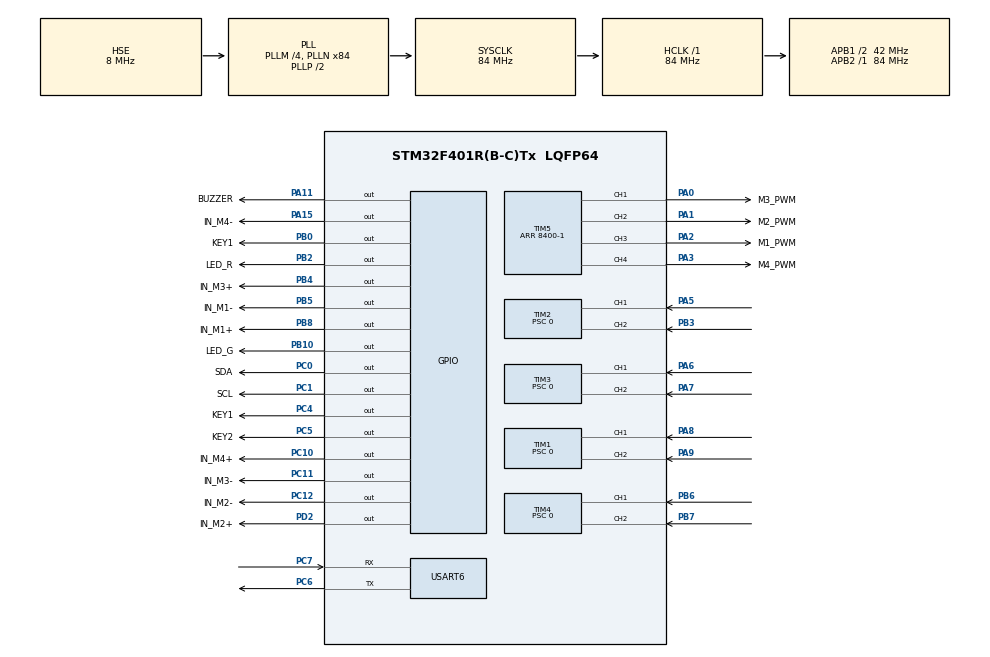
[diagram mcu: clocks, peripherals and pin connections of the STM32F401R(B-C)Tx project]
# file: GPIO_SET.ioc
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Mcu.Family=STM32F4
Mcu.Name=STM32F401R(B-C)Tx
Mcu.Package=LQFP64
NVIC.PriorityGroup=NVIC_PRIORITYGROUP_4
NVIC.TIM5_IRQn=true\:0\:0\:false\:false\:true\:true\:true\:true
NVIC.USART6_IRQn=true\:0\:0\:false\:false\:true\:true\:true\:true
PA0-WKUP.GPIO_Label=M3_PWM
PA0-WKUP.Signal=S_TIM5_CH1
PA1.GPIO_Label=M2_PWM
PA1.Signal=S_TIM5_CH2
PA11.GPIO_Label=BUZZER
PA11.Signal=GPIO_Output
PA13.Mode=Serial_Wire
PA13.Signal=SYS_JTMS-SWDIO
PA14.Mode=Serial_Wire
PA14.Signal=SYS_JTCK-SWCLK
PA15.GPIO_Label=IN_M4-
PA15.Signal=GPIO_Output
PA2.GPIO_Label=M1_PWM
PA2.Signal=S_TIM5_CH3
PA3.GPIO_Label=M4_PWM
PA3.Signal=S_TIM5_CH4
PA5.Signal=S_TIM2_CH1_ETR
PA6.Signal=S_TIM3_CH1
PA7.Signal=S_TIM3_CH2
PA8.Signal=S_TIM1_CH1
PA9.Signal=S_TIM1_CH2
PB0.GPIO_Label=KEY1
PB0.Signal=GPIO_Output
PB10.GPIO_Label=LED_G
PB10.GPIO_Speed=GPIO_SPEED_FREQ_VERY_HIGH
PB10.Signal=GPIO_Output
PB2.GPIO_Label=LED_R
PB2.Signal=GPIO_Output
PB3.Signal=S_TIM2_CH2
PB4.GPIO_Label=IN_M3+
PB4.Signal=GPIO_Output
PB5.GPIO_Label=IN_M1-
PB5.Signal=GPIO_Output
PB6.Signal=S_TIM4_CH1
PB7.Signal=S_TIM4_CH2
PB8.GPIO_Label=IN_M1+
PB8.Signal=GPIO_Output
PC0.GPIO_Label=SDA
PC0.Signal=GPIO_Output
PC1.GPIO_Label=SCL
PC1.Signal=GPIO_Output
PC10.GPIO_Label=IN_M4+
PC10.Signal=GPIO_Output
PC11.GPIO_Label=IN_M3-
PC11.Signal=GPIO_Output
PC12.GPIO_Label=IN_M2-
PC12.Signal=GPIO_Output
PC4.GPIO_Label=KEY1
PC4.Signal=GPIO_Output
PC5.GPIO_Label=KEY2
PC5.Signal=GPIO_Output
PC6.Mode=Asynchronous
PC6.Signal=USART6_TX
PC7.Mode=Asynchronous
PC7.Signal=USART6_RX
PD2.GPIO_Label=IN_M2+
PD2.Signal=GPIO_Output
PH0\ -\ OSC_IN.Mode=HSE-External-Oscillator
PH0\ -\ OSC_IN.Signal=RCC_OSC_IN
PH1\ -\ OSC_OUT.Mode=HSE-External-Oscillator
PH1\ -\ OSC_OUT.Signal=RCC_OSC_OUT
ProjectManager.HeapSize=0x200
ProjectManager.StackSize=0x400
ProjectManager.TargetToolchain=Makefile
RCC.48MHZClocksFreq_Value=42000000
RCC.AHBFreq_Value=84000000
RCC.APB1CLKDivider=RCC_HCLK_DIV2
RCC.APB1Freq_Value=42000000
RCC.APB1TimFreq_Value=84000000
RCC.APB2Freq_Value=84000000
RCC.APB2TimFreq_Value=84000000
RCC.CortexFreq_Value=84000000
RCC.HCLKFreq_Value=84000000
RCC.HSE_VALUE=8000000
RCC.HSI_VALUE=16000000
RCC.LSE_VALUE=32768
RCC.PLLM=4
RCC.PLLN=84
RCC.PLLSourceVirtual=RCC_PLLSOURCE_HSE
RCC.SYSCLKFreq_VALUE=84000000
RCC.SYSCLKSource=RCC_SYSCLKSOURCE_PLLCLK
RCC.VCOOutputFreq_Value=168000000
SH.S_TIM1_CH1.0=TIM1_CH1,Encoder_Interface
SH.S_TIM1_CH2.0=TIM1_CH2,Encoder_Interface
SH.S_TIM2_CH1_ETR.0=TIM2_CH1,Encoder_Interface
SH.S_TIM2_CH2.0=TIM2_CH2,Encoder_Interface
SH.S_TIM3_CH1.0=TIM3_CH1,Encoder_Interface
SH.S_TIM3_CH2.0=TIM3_CH2,Encoder_Interface
SH.S_TIM4_CH1.0=TIM4_CH1,Encoder_Interface
SH.S_TIM4_CH2.0=TIM4_CH2,Encoder_Interface
SH.S_TIM5_CH1.0=TIM5_CH1,PWM Generation1 CH1
SH.S_TIM5_CH2.0=TIM5_CH2,PWM Generation2 CH2
SH.S_TIM5_CH3.0=TIM5_CH3,PWM Generation3 CH3
SH.S_TIM5_CH4.0=TIM5_CH4,PWM Generation4 CH4
TIM1.EncoderMode=TIM_ENCODERMODE_TI12
TIM1.Prescaler=0
TIM2.EncoderMode=TIM_ENCODERMODE_TI12
TIM2.Prescaler=0
TIM3.EncoderMode=TIM_ENCODERMODE_TI12
TIM3.Prescaler=0
TIM4.EncoderMode=TIM_ENCODERMODE_TI12
TIM4.Prescaler=0
TIM5.AutoReloadPreload=TIM_AUTORELOAD_PRELOAD_ENABLE
TIM5.Channel-PWM\ Generation1\ CH1=TIM_CHANNEL_1
TIM5.Channel-PWM\ Generation2\ CH2=TIM_CHANNEL_2
TIM5.Channel-PWM\ Generation3\ CH3=TIM_CHANNEL_3
TIM5.Channel-PWM\ Generation4\ CH4=TIM_CHANNEL_4
TIM5.Period=8400-1
TIM5.Pulse-PWM\ Generation1\ CH1=8000
TIM5.Pulse-PWM\ Generation2\ CH2=8000
TIM5.Pulse-PWM\ Generation3\ CH3=8000
TIM5.Pulse-PWM\ Generation4\ CH4=8000
USART6.VirtualMode=VM_ASYNC
VP_TIM5_VS_ClockSourceINT.Mode=Internal
board=custom

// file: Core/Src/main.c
/* USER CODE BEGIN Header */
/**
  ******************************************************************************
  * @file           : main.c
  * @brief          : Main program body
  ******************************************************************************
  * @attention
  *
  * Copyright (c) 2024 STMicroelectronics.
  * All rights reserved.
  *
  * This software is licensed under terms that can be found in the LICENSE file
  * in the root directory of this software component.
  * If no LICENSE file comes with this software, it is provided AS-IS.
  *
  ******************************************************************************
  */
/* USER CODE END Header */
#include "main.h"
#include "tim.h"
#include "usart.h"
#include "gpio.h"

/* USER CODE BEGIN Includes */
#include "headfile.h"
/* USER CODE END Includes */

void SystemClock_Config(void);

int main(void)
{

  /* MCU Configuration--------------------------------------------------------*/

  /* Reset of all peripherals, Initializes the Flash interface and the Systick. */
  HAL_Init();

  /* Configure the system clock */
  SystemClock_Config();

  /* Initialize all configured peripherals */
  MX_GPIO_Init();
  MX_TIM1_Init();
  MX_TIM2_Init();
  MX_TIM3_Init();
  MX_TIM4_Init();
  MX_TIM5_Init();
  MX_USART6_UART_Init();
  /* USER CODE BEGIN 2 */
  task_init();
  /* USER CODE END 2 */

  /* Infinite loop */
  while (1)
  {

    /* USER CODE BEGIN 3 */
    task_do();
  }
  /* USER CODE END 3 */
}

void SystemClock_Config(void)
{
  RCC_OscInitTypeDef RCC_OscInitStruct = {0};
  RCC_ClkInitTypeDef RCC_ClkInitStruct = {0};

  /** Configure the main internal regulator output voltage
  */
  __HAL_RCC_PWR_CLK_ENABLE();
  __HAL_PWR_VOLTAGESCALING_CONFIG(PWR_REGULATOR_VOLTAGE_SCALE2);

  /** Initializes the RCC Oscillators according to the specified parameters
  * in the RCC_OscInitTypeDef structure.
  */
  RCC_OscInitStruct.OscillatorType = RCC_OSCILLATORTYPE_HSE;
  RCC_OscInitStruct.HSEState = RCC_HSE_ON;
  RCC_OscInitStruct.PLL.PLLState = RCC_PLL_ON;
  RCC_OscInitStruct.PLL.PLLSource = RCC_PLLSOURCE_HSE;
  RCC_OscInitStruct.PLL.PLLM = 4;
  RCC_OscInitStruct.PLL.PLLN = 84;
  RCC_OscInitStruct.PLL.PLLP = RCC_PLLP_DIV2;
  RCC_OscInitStruct.PLL.PLLQ = 4;
  if (HAL_RCC_OscConfig(&RCC_OscInitStruct) != HAL_OK)
  {
    Error_Handler();
  }

  /** Initializes the CPU, AHB and APB buses clocks
  */
  RCC_ClkInitStruct.ClockType = RCC_CLOCKTYPE_HCLK|RCC_CLOCKTYPE_SYSCLK
                              |RCC_CLOCKTYPE_PCLK1|RCC_CLOCKTYPE_PCLK2;
  RCC_ClkInitStruct.SYSCLKSource = RCC_SYSCLKSOURCE_PLLCLK;
  RCC_ClkInitStruct.AHBCLKDivider = RCC_SYSCLK_DIV1;
  RCC_ClkInitStruct.APB1CLKDivider = RCC_HCLK_DIV2;
  RCC_ClkInitStruct.APB2CLKDivider = RCC_HCLK_DIV1;

  if (HAL_RCC_ClockConfig(&RCC_ClkInitStruct, FLASH_LATENCY_2) != HAL_OK)
  {
    Error_Handler();
  }
}

void Error_Handler(void)
{
  __disable_irq();
  while (1)
  {
  }
}
